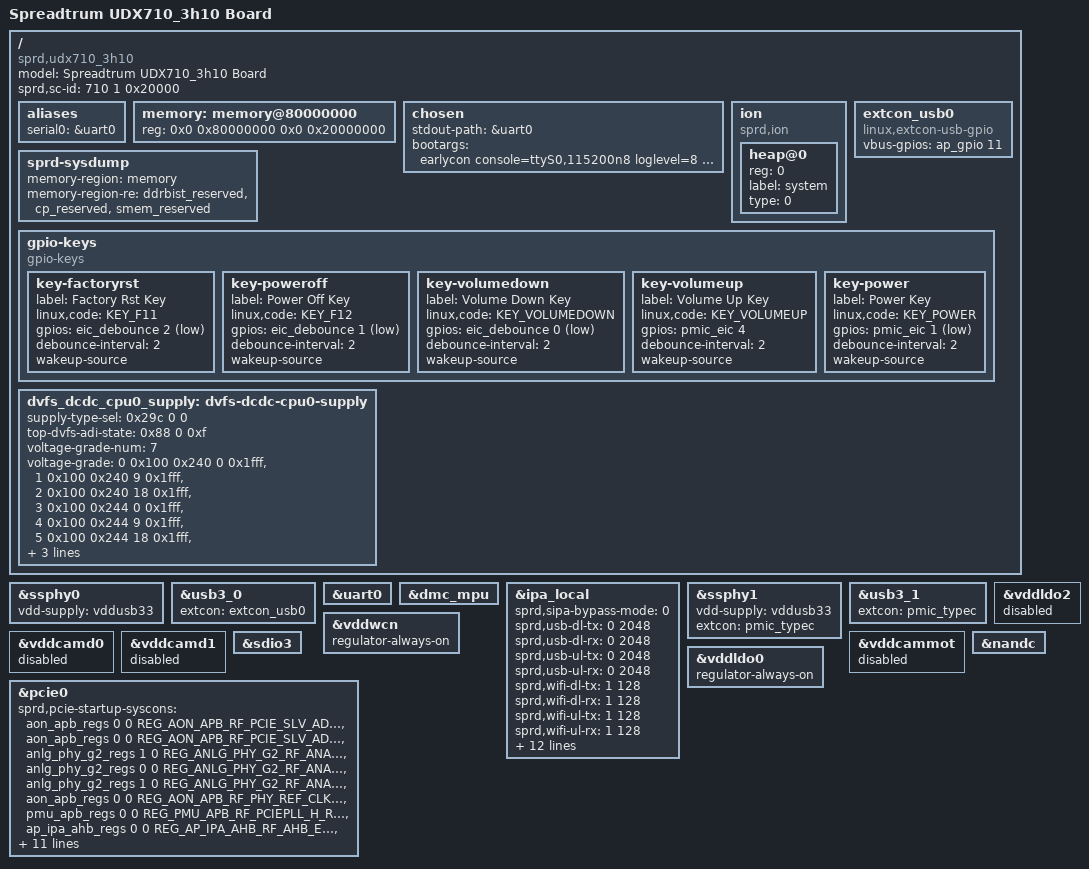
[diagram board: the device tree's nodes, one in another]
/*
 * Spreadtrum orca udx710 board DTS file
 *
 * Copyright (C) 2017,2018 Spreadtrum Communications Inc.
 *
 * This file is licensed under a dual GPLv2 or X11 license.
 */
/dts-v1/;

#include <dt-bindings/input/input.h>
#include <dt-bindings/gpio/gpio.h>

#include "udx710.dtsi"
#include "sc2730.dtsi"
#include "udx710-mach.dtsi"

/ {
	model = "Spreadtrum UDX710_3h10 Board";

	compatible = "sprd,udx710_3h10", "sprd,udx710";

	sprd,sc-id = <710 1 0x20000>;

	aliases {
		serial0 = &uart0;
	};

	memory: memory@80000000 {
		device_type = "memory";
		reg = <0x0 0x80000000 0x0 0x20000000>;
	};

	chosen {
		stdout-path = &uart0;
		bootargs = "earlycon console=ttyS0,115200n8 loglevel=8 rdinit=/linuxrc root=/dev/ram0 ro androidboot.hardware=udx710_3h10 androidboot.selinux=permissive swiotlb=64k androidboot.dtbo_idx=0 printk.devkmsg=on";
	};

	ion {
		compatible = "sprd,ion";
		#address-cells = <1>;
		#size-cells = <0>;

		heap@0 {
			reg = <0>;
			label = "system";
			type = <0>;
		};
	};

	extcon_usb0: extcon_usb0 {
		compatible = "linux,extcon-usb-gpio";

		vbus-gpios = <&ap_gpio 11 GPIO_ACTIVE_HIGH>;
	};
	sprd-sysdump {
		memory-region = <&memory>;
		memory-region-re = <&ddrbist_reserved>, <&cp_reserved>, <&smem_reserved>;
	};

	gpio-keys {
		compatible = "gpio-keys";

		key-factoryrst {
			label = "Factory Rst Key";
			linux,code = <KEY_F11>;
			gpios = <&eic_debounce 2 GPIO_ACTIVE_LOW>;
			debounce-interval = <2>;
			wakeup-source;
		};

		key-poweroff {
			label = "Power Off Key";
			linux,code = <KEY_F12>;
			gpios = <&eic_debounce 1 GPIO_ACTIVE_LOW>;
			debounce-interval = <2>;
			wakeup-source;
		};

		key-volumedown {
			label = "Volume Down Key";
			linux,code = <KEY_VOLUMEDOWN>;
			gpios = <&eic_debounce 0 GPIO_ACTIVE_LOW>;
			debounce-interval = <2>;
			wakeup-source;
		};

		key-volumeup {
			label = "Volume Up Key";
			linux,code = <KEY_VOLUMEUP>;
			gpios = <&pmic_eic 4 GPIO_ACTIVE_HIGH>;
			debounce-interval = <2>;
			wakeup-source;
		};

		key-power {
			label = "Power Key";
			linux,code = <KEY_POWER>;
			gpios = <&pmic_eic 1 GPIO_ACTIVE_LOW>;
			debounce-interval = <2>;
			wakeup-source;
		};
	};

	dvfs_dcdc_cpu0_supply: dvfs-dcdc-cpu0-supply {
		supply-type-sel = <0x29c 0 0>;
		top-dvfs-adi-state = <0x88 0 0xf>;
		voltage-grade-num = <7>;
		voltage-grade = <0 0x100 0x240 0 0x1fff>,
			<1 0x100 0x240 9 0x1fff>,
			<2 0x100 0x240 18 0x1fff>,
			<3 0x100 0x244 0 0x1fff>,
			<4 0x100 0x244 9 0x1fff>,
			<5 0x100 0x244 18 0x1fff>,
			<6 0x100 0x248 0 0x1fff>;
		tuning-latency-us = <200>;
		chnl-in-i2c = <0>;
	};
};

&ssphy0 {
	vdd-supply = <&vddusb33>;
	status = "okay";
};

&usb3_0 {
	extcon = <&extcon_usb0>;
	status = "okay";
};

&uart0 {
	status = "ok";
};

&dmc_mpu {
	status = "okay";
};

&ipa_local {
	sprd,sipa-bypass-mode = <0>;

	sprd,usb-dl-tx = <0 2048>;
	sprd,usb-dl-rx = <0 2048>;
	sprd,usb-ul-tx = <0 2048>;
	sprd,usb-ul-rx = <0 2048>;
	sprd,wifi-dl-tx = <1 128>;
	sprd,wifi-dl-rx = <1 128>;
	sprd,wifi-ul-tx = <1 128>;
	sprd,wifi-ul-rx = <1 128>;
	sprd,ap-eth-dl-tx = <0 2048>;
	sprd,ap-eth-dl-rx = <0 2048>;
	sprd,ap-eth-ul-tx = <0 2048>;
	sprd,ap-eth-ul-rx = <0 2048>;
	sprd,ap-ip-dl-tx = <0 2048>;
	sprd,ap-ip-dl-rx = <0 2048>;
	sprd,ap-ip-ul-tx = <0 2048>;
	sprd,ap-ip-ul-rx = <0 2048>;
	sprd,cp-dl-tx = <0 0>;
	sprd,cp-dl-rx = <0 0>;
	sprd,cp-ul-tx = <0 0>;
	sprd,cp-ul-rx = <0 0>;
};

&ssphy1 {
	vdd-supply = <&vddusb33>;
	extcon = <&pmic_typec>;
	status = "okay";
};

&usb3_1 {
	extcon = <&pmic_typec>;
	status = "okay";
};

&vddwcn {
	regulator-always-on;
};

&vddcamd0 {
	status = "disabled";
};

&vddcamd1 {
	status = "disabled";
};

&vddcammot {
	status = "disabled";
};

&vddldo0 {
	regulator-always-on;
};

&vddldo2 {
	status = "disabled";
};

&sdio3 {
	status = "okay";
};

&nandc {
	status = "okay";
};

&pcie0 {
	sprd,pcie-startup-syscons =
		<&aon_apb_regs 0 0
			REG_AON_APB_RF_PCIE_SLV_ADDR_OFFSET
			MASK_AON_APB_RF_PCIE_SLV_ADDR_OFFSET
			0x1>,
		<&aon_apb_regs 0 0
			REG_AON_APB_RF_PCIE_SLV_ADDR_OFFSET
			MASK_AON_APB_RF_PCIE_MOD_SEL
			0x10000>,
		<&anlg_phy_g2_regs 1 0
			REG_ANLG_PHY_G2_RF_ANALOG_PCIEPLL_H_PCIEPLLH_CTRL6
			0x3000	/* no corresponding macro */
			0x1000>,
		<&anlg_phy_g2_regs 0 0
			REG_ANLG_PHY_G2_RF_ANALOG_PCIE_GEN2_1T1R_REG_SEL_CFG_0
			MASK_ANLG_PHY_G2_RF_DBG_SEL_ANALOG_PCIE_GEN2_1T1R_PIPE_RESERVEDIN
			0x1>,
		<&anlg_phy_g2_regs 1 0
			REG_ANLG_PHY_G2_RF_ANALOG_PCIE_GEN2_1T1R_ANA_PCIE31_CTRL2
			MASK_ANLG_PHY_G2_RF_ANALOG_PCIE_GEN2_1T1R_PIPE_RESERVEDIN
			0x10000>,
		<&aon_apb_regs 0 0
			REG_AON_APB_RF_PHY_REF_CLK_EN
			MASK_AON_APB_RF_PCIE_PHY_REF_CLK_EN
			0x200>,
		<&pmu_apb_regs 0 0
			REG_PMU_APB_RF_PCIEPLL_H_REL_CFG
			MASK_PMU_APB_RF_PCIEPLL_H_FRC_OFF
			0x0>,
		<&ap_ipa_ahb_regs 0 0
			REG_AP_IPA_AHB_RF_AHB_EB
			MASK_AP_IPA_AHB_RF_PCIE_SEL
			0x0>,
		<&ap_ipa_ahb_regs 0 0
			REG_AP_IPA_AHB_RF_AHB_EB
			MASK_AP_IPA_AHB_RF_PCIE_AUX_EB
			0x40>,
		<&ap_ipa_ahb_regs 0 0
			REG_AP_IPA_AHB_RF_AHB_EB
			MASK_AP_IPA_AHB_RF_PCIE_EB
			0x20>,
		<&pmu_apb_regs 0 0
			REG_PMU_APB_RF_PCIE_SLP_CFG
			MASK_PMU_APB_RF_PCIE_CLKREQ_PLL_GATE_MASK
			0x0>,
		<&pmu_apb_regs 0 150
			REG_PMU_APB_RF_PCIE_SLP_CFG
			MASK_PMU_APB_RF_REG_PERST_N_ASSERT
			0x10>,
		<&pmu_apb_regs 0 0
			REG_PMU_APB_RF_PCIE_SLP_CFG
			MASK_PMU_APB_RF_REG_PERST_N_ASSERT
			0x0>;

	sprd,pcie-resume-syscons =
		<&ap_ipa_ahb_regs 0 0
			REG_AP_IPA_AHB_RF_AHB_EB
			MASK_AP_IPA_AHB_RF_PCIE_EB
			0x20>,
		<&pmu_apb_regs 0 0
			REG_PMU_APB_RF_PCIE_SLP_CFG
			MASK_PMU_APB_RF_REG_PERST_N_ASSERT
			0x0>;

	sprd,pcie-suspend-syscons =
		<&pmu_apb_regs 0 0
			REG_PMU_APB_RF_PCIE_SLP_CFG
			MASK_PMU_APB_RF_REG_PERST_N_ASSERT
			0x10>,
		<&ap_ipa_ahb_regs 0 0
			REG_AP_IPA_AHB_RF_AHB_EB
			MASK_AP_IPA_AHB_RF_PCIE_EB
			0x0>;

	status = "okay";
};
